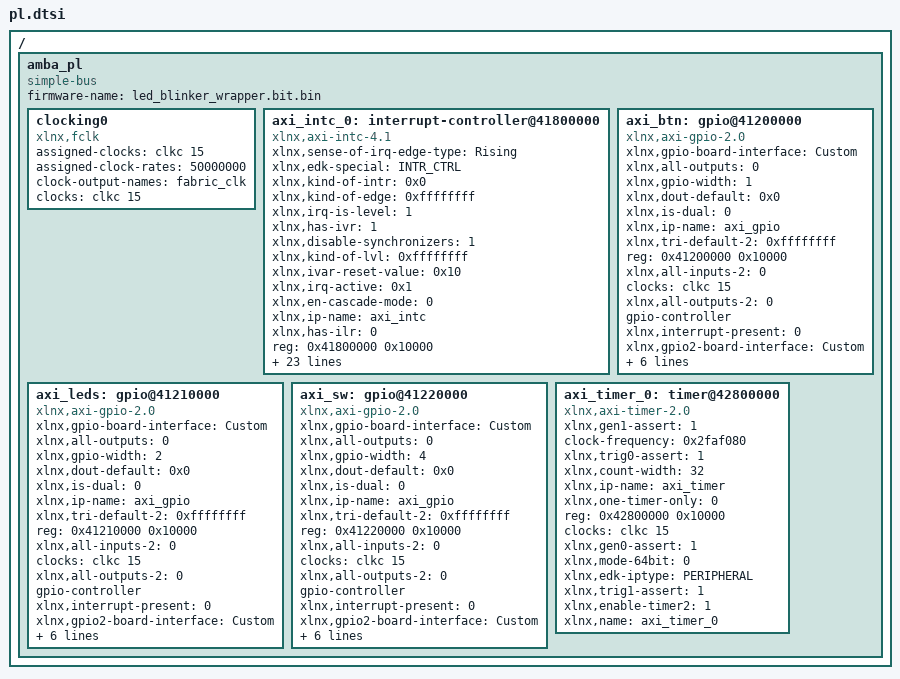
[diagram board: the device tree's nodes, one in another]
/ {
	amba_pl: amba_pl {
		ranges;
		compatible = "simple-bus";
		#address-cells = <1>;
		#size-cells = <1>;
		firmware-name = "led_blinker_wrapper.bit.bin";
		clocking0: clocking0 {
			compatible = "xlnx,fclk";
			assigned-clocks = <&clkc 15>;
			assigned-clock-rates = <50000000>;
			#clock-cells = <0>;
			clock-output-names = "fabric_clk";
			clocks = <&clkc 15>;
		};
		axi_intc_0: interrupt-controller@41800000 {
			#interrupt-cells = <2>;
			xlnx,sense-of-irq-edge-type = "Rising";
			xlnx,edk-special = "INTR_CTRL";
			xlnx,kind-of-intr = <0x0>;
			xlnx,kind-of-edge = <0xffffffff>;
			xlnx,irq-is-level = <1>;
			xlnx,has-ivr = <1>;
			compatible = "xlnx,axi-intc-4.1" , "xlnx,xps-intc-1.00.a";
			xlnx,disable-synchronizers = <1>;
			xlnx,kind-of-lvl = <0xffffffff>;
			xlnx,ivar-reset-value = <0x10>;
			xlnx,irq-active = <0x1>;
			xlnx,en-cascade-mode = <0>;
			xlnx,ip-name = "axi_intc";
			xlnx,has-ilr = <0>;
			reg = <0x41800000 0x10000>;
			xlnx,addr-width = <0x20>;
			clocks = <&clkc 15>;
			xlnx,s-axi-aclk-freq-mhz = <50>;
			xlnx,num-sw-intr = <0>;
			xlnx,irq-connection = <0>;
			xlnx,num-intr-inputs = <0x1>;
			xlnx,has-sie = <1>;
			xlnx,enable-async = <0>;
			xlnx,has-cie = <1>;
			xlnx,num-sync-ff = <2>;
			xlnx,edk-iptype = "PERIPHERAL";
			xlnx,mb-clk-not-connected = <1>;
			xlnx,has-ipr = <1>;
			xlnx,intc-type = <0x0>;
			xlnx,sense-of-irq-level-type = "Active_High";
			xlnx,cascade-master = <0>;
			xlnx,processor-clk-freq-mhz = <100>;
			status = "okay";
			xlnx,is-fast = <0x0>;
			clock-names = "s_axi_aclk";
			xlnx,has-fast = <0>;
			xlnx,ivar-rst-val = <0x10>;
			interrupt-controller;
			xlnx,async-intr = <0xfffffffe>;
			xlnx,name = "axi_intc_0";
		};
		axi_btn: gpio@41200000 {
			xlnx,gpio-board-interface = "Custom";
			compatible = "xlnx,axi-gpio-2.0" , "xlnx,xps-gpio-1.00.a";
			xlnx,all-outputs = <0>;
			#gpio-cells = <2>;
			xlnx,gpio-width = <1>;
			xlnx,dout-default = <0x0>;
			xlnx,is-dual = <0>;
			xlnx,ip-name = "axi_gpio";
			xlnx,tri-default-2 = <0xffffffff>;
			reg = <0x41200000 0x10000>;
			xlnx,all-inputs-2 = <0>;
			clocks = <&clkc 15>;
			xlnx,all-outputs-2 = <0>;
			gpio-controller;
			device_type = "gpio";
			xlnx,interrupt-present = <0>;
			xlnx,gpio2-board-interface = "Custom";
			xlnx,edk-iptype = "PERIPHERAL";
			xlnx,dout-default-2 = <0x0>;
			status = "okay";
			xlnx,gpio2-width = <32>;
			clock-names = "s_axi_aclk";
			xlnx,tri-default = <0xffffffff>;
			xlnx,name = "axi_btn";
			xlnx,all-inputs = <0>;
		};
		axi_leds: gpio@41210000 {
			xlnx,gpio-board-interface = "Custom";
			compatible = "xlnx,axi-gpio-2.0" , "xlnx,xps-gpio-1.00.a";
			xlnx,all-outputs = <0>;
			#gpio-cells = <2>;
			xlnx,gpio-width = <2>;
			xlnx,dout-default = <0x0>;
			xlnx,is-dual = <0>;
			xlnx,ip-name = "axi_gpio";
			xlnx,tri-default-2 = <0xffffffff>;
			reg = <0x41210000 0x10000>;
			xlnx,all-inputs-2 = <0>;
			clocks = <&clkc 15>;
			xlnx,all-outputs-2 = <0>;
			gpio-controller;
			device_type = "gpio";
			xlnx,interrupt-present = <0>;
			xlnx,gpio2-board-interface = "Custom";
			xlnx,edk-iptype = "PERIPHERAL";
			xlnx,dout-default-2 = <0x0>;
			status = "okay";
			xlnx,gpio2-width = <32>;
			clock-names = "s_axi_aclk";
			xlnx,tri-default = <0xffffffff>;
			xlnx,name = "axi_leds";
			xlnx,all-inputs = <0>;
		};
		axi_sw: gpio@41220000 {
			xlnx,gpio-board-interface = "Custom";
			compatible = "xlnx,axi-gpio-2.0" , "xlnx,xps-gpio-1.00.a";
			xlnx,all-outputs = <0>;
			#gpio-cells = <2>;
			xlnx,gpio-width = <4>;
			xlnx,dout-default = <0x0>;
			xlnx,is-dual = <0>;
			xlnx,ip-name = "axi_gpio";
			xlnx,tri-default-2 = <0xffffffff>;
			reg = <0x41220000 0x10000>;
			xlnx,all-inputs-2 = <0>;
			clocks = <&clkc 15>;
			xlnx,all-outputs-2 = <0>;
			gpio-controller;
			device_type = "gpio";
			xlnx,interrupt-present = <0>;
			xlnx,gpio2-board-interface = "Custom";
			xlnx,edk-iptype = "PERIPHERAL";
			xlnx,dout-default-2 = <0x0>;
			status = "okay";
			xlnx,gpio2-width = <32>;
			clock-names = "s_axi_aclk";
			xlnx,tri-default = <0xffffffff>;
			xlnx,name = "axi_sw";
			xlnx,all-inputs = <0>;
		};
		axi_timer_0: timer@42800000 {
			compatible = "xlnx,axi-timer-2.0" , "xlnx,xps-timer-1.00.a";
			xlnx,gen1-assert = <1>;
			clock-frequency = <0x2faf080>;
			xlnx,trig0-assert = <1>;
			xlnx,count-width = <32>;
			xlnx,ip-name = "axi_timer";
			xlnx,one-timer-only = <0>;
			reg = <0x42800000 0x10000>;
			clocks = <&clkc 15>;
			xlnx,gen0-assert = <1>;
			xlnx,mode-64bit = <0>;
			xlnx,edk-iptype = "PERIPHERAL";
			status = "okay";
			xlnx,trig1-assert = <1>;
			clock-names = "s_axi_aclk";
			xlnx,enable-timer2 = <1>;
			xlnx,name = "axi_timer_0";
		};
	};
};
